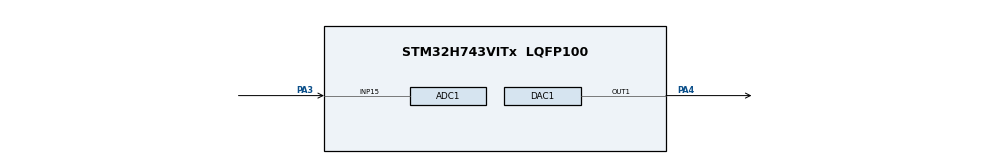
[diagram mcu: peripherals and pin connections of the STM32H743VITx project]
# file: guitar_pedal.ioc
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ADC1.Channel-0\#ChannelRegularConversion=ADC_CHANNEL_15
ADC1.ConversionDataManagement=ADC_CONVERSIONDATA_DMA_CIRCULAR
ADC1.ExternalTrigConv=ADC_EXTERNALTRIG_T6_TRGO
ADC1.NbrOfConversion=1
ADC1.NbrOfConversionFlag=1
ADC1.OffsetNumber-0\#ChannelRegularConversion=ADC_OFFSET_NONE
ADC1.OffsetSignedSaturation-0\#ChannelRegularConversion=DISABLE
ADC1.Rank-0\#ChannelRegularConversion=1
ADC1.SamplingTime-0\#ChannelRegularConversion=ADC_SAMPLETIME_1CYCLE_5
ADC1.master=1
DAC1.DAC_Channel-DAC_OUT1=DAC_CHANNEL_1
DAC1.DAC_Trigger-DAC_OUT1=DAC_TRIGGER_T6_TRGO
Dma.ADC1.0.Direction=DMA_PERIPH_TO_MEMORY
Dma.ADC1.0.EventEnable=DISABLE
Dma.ADC1.0.FIFOMode=DMA_FIFOMODE_DISABLE
Dma.ADC1.0.Instance=DMA1_Stream0
Dma.ADC1.0.MemDataAlignment=DMA_MDATAALIGN_HALFWORD
Dma.ADC1.0.MemInc=DMA_MINC_ENABLE
Dma.ADC1.0.Mode=DMA_CIRCULAR
Dma.ADC1.0.PeriphDataAlignment=DMA_PDATAALIGN_HALFWORD
Dma.ADC1.0.PeriphInc=DMA_PINC_DISABLE
Dma.ADC1.0.Polarity=HAL_DMAMUX_REQ_GEN_RISING
Dma.ADC1.0.Priority=DMA_PRIORITY_LOW
Dma.ADC1.0.RequestNumber=1
Dma.ADC1.0.SignalID=NONE
Dma.ADC1.0.SyncEnable=DISABLE
Dma.ADC1.0.SyncPolarity=HAL_DMAMUX_SYNC_NO_EVENT
Dma.ADC1.0.SyncRequestNumber=1
Dma.ADC1.0.SyncSignalID=NONE
Dma.DAC1_CH1.1.Direction=DMA_MEMORY_TO_PERIPH
Dma.DAC1_CH1.1.EventEnable=DISABLE
Dma.DAC1_CH1.1.FIFOMode=DMA_FIFOMODE_DISABLE
Dma.DAC1_CH1.1.Instance=DMA1_Stream1
Dma.DAC1_CH1.1.MemDataAlignment=DMA_MDATAALIGN_HALFWORD
Dma.DAC1_CH1.1.MemInc=DMA_MINC_ENABLE
Dma.DAC1_CH1.1.Mode=DMA_CIRCULAR
Dma.DAC1_CH1.1.PeriphDataAlignment=DMA_PDATAALIGN_HALFWORD
Dma.DAC1_CH1.1.PeriphInc=DMA_PINC_DISABLE
Dma.DAC1_CH1.1.Polarity=HAL_DMAMUX_REQ_GEN_RISING
Dma.DAC1_CH1.1.Priority=DMA_PRIORITY_LOW
Dma.DAC1_CH1.1.RequestNumber=1
Dma.DAC1_CH1.1.SignalID=NONE
Dma.DAC1_CH1.1.SyncEnable=DISABLE
Dma.DAC1_CH1.1.SyncPolarity=HAL_DMAMUX_SYNC_NO_EVENT
Dma.DAC1_CH1.1.SyncRequestNumber=1
Dma.DAC1_CH1.1.SyncSignalID=NONE
Dma.Request0=ADC1
Dma.Request1=DAC1_CH1
Mcu.Family=STM32H7
Mcu.Name=STM32H743VITx
Mcu.Package=LQFP100
NVIC.DMA1_Stream0_IRQn=true\:0\:0\:false\:false\:true\:false\:true\:true
NVIC.DMA1_Stream1_IRQn=true\:0\:0\:false\:false\:true\:false\:true\:true
NVIC.PriorityGroup=NVIC_PRIORITYGROUP_4
PA3.Signal=ADCx_INP15
PA4.Signal=COMP_DAC11_group
PH0-OSC_IN\ (PH0).Mode=HSE-External-Oscillator
PH0-OSC_IN\ (PH0).Signal=RCC_OSC_IN
PH1-OSC_OUT\ (PH1).Mode=HSE-External-Oscillator
PH1-OSC_OUT\ (PH1).Signal=RCC_OSC_OUT
ProjectManager.HeapSize=0x200
ProjectManager.StackSize=0x400
ProjectManager.TargetToolchain=CMake
RCC.ADCFreq_Value=75000000
RCC.APB1Freq_Value=120000000
RCC.APB2Freq_Value=120000000
RCC.APB3Freq_Value=120000000
RCC.APB4Freq_Value=120000000
RCC.CortexFreq_Value=480000000
RCC.D1PPRE=RCC_APB3_DIV2
RCC.D2PPRE1=RCC_APB1_DIV2
RCC.D2PPRE2=RCC_APB2_DIV2
RCC.D3PPRE=RCC_APB4_DIV2
RCC.DIVM1=8
RCC.DIVM2=4
RCC.DIVN1=120
RCC.DIVN2=9
RCC.HCLKFreq_Value=240000000
RCC.HPRE=RCC_HCLK_DIV2
RCC.PLL2FRACN=3072
RCC.PLLFRACN=0
RCC.SYSCLKFreq_VALUE=480000000
RCC.SYSCLKSource=RCC_SYSCLKSOURCE_PLLCLK
RCC.USBFreq_Value=480000000
SH.ADCx_INP15.0=ADC1_INP15,IN15-Single-Ended
SH.COMP_DAC11_group.0=DAC1_OUT1,DAC_OUT1
TIM6.Period=5000-1
TIM6.Prescaler=0
TIM6.TIM_MasterOutputTrigger=TIM_TRGO_UPDATE
VP_MEMORYMAP_VS_MEMORYMAP.Mode=CurAppReg
VP_TIM6_VS_ClockSourceINT.Mode=Enable_Timer
board=custom

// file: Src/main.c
/* USER CODE BEGIN Header */
/**
 ******************************************************************************
 * @file           : main.c
 * @brief          : Main program body
 ******************************************************************************
 * @attention
 *
 * Copyright (c) 2025 STMicroelectronics.
 * All rights reserved.
 *
 * This software is licensed under terms that can be found in the LICENSE file
 * in the root directory of this software component.
 * If no LICENSE file comes with this software, it is provided AS-IS.
 *
 ******************************************************************************
 */
/* USER CODE END Header */
#include "main.h"
#include "adc.h"
#include "dac.h"
#include "dma.h"
#include "tim.h"
#include "gpio.h"

/* USER CODE BEGIN Includes */
#include "dsp.h"

/* USER CODE END Includes */

/* USER CODE BEGIN PD */
#define N 256
#define halfN 128

/* USER CODE END PD */

/* USER CODE BEGIN PV */
// DMA1 cannot access DTCM RAM on STM32H7; place buffers in D2 SRAM.
__attribute__((section(".dma_buffer"))) uint16_t adcBuffer[N];
__attribute__((section(".dma_buffer"))) uint16_t dacBuffer[N];

volatile uint32_t dbg_halfCpltCount = 0;
volatile uint32_t dbg_cpltCount = 0;
volatile uint16_t dbg_adcSnapshot[4];
volatile uint16_t dbg_adcMin = 0xFFFF;
volatile uint16_t dbg_adcMax = 0;
volatile uint16_t dbg_dacSnapshot[4];

volatile uint32_t dbg_init_progress = 0;
volatile uint32_t dbg_reset_cause = 0;
volatile uint32_t dbg_fault_type = 0;
volatile uint32_t dbg_fault_CFSR = 0;
volatile uint32_t dbg_fault_HFSR = 0;
volatile uint32_t dbg_fault_MMFAR = 0;
volatile uint32_t dbg_fault_BFAR = 0;
volatile uint32_t dbg_error_handler_hit = 0;

/* USER CODE END PV */

void SystemClock_Config(void);
/* USER CODE BEGIN PFP */
void dsp_algorithm(uint16_t *input, uint16_t *output, int startindex,
                   int endindex);

/* USER CODE END PFP */

int main(void)
{

  /* USER CODE BEGIN 1 */
  // Force-reset peripherals: a debug-reset leaves them mid-operation.
  __HAL_RCC_DMA1_CLK_ENABLE();
  __HAL_RCC_DMA1_FORCE_RESET();
  __HAL_RCC_DMA1_RELEASE_RESET();

  NVIC_DisableIRQ(DMA1_Stream0_IRQn);
  NVIC_DisableIRQ(DMA1_Stream1_IRQn);
  NVIC_DisableIRQ(DMAMUX1_OVR_IRQn);
  NVIC_ClearPendingIRQ(DMA1_Stream0_IRQn);
  NVIC_ClearPendingIRQ(DMA1_Stream1_IRQn);
  NVIC_ClearPendingIRQ(DMAMUX1_OVR_IRQn);

  __HAL_RCC_ADC12_CLK_ENABLE();
  __HAL_RCC_ADC12_FORCE_RESET();
  __HAL_RCC_ADC12_RELEASE_RESET();

  __HAL_RCC_DAC12_CLK_ENABLE();
  __HAL_RCC_DAC12_FORCE_RESET();
  __HAL_RCC_DAC12_RELEASE_RESET();

  __HAL_RCC_TIM6_CLK_ENABLE();
  __HAL_RCC_TIM6_FORCE_RESET();
  __HAL_RCC_TIM6_RELEASE_RESET();

  dbg_reset_cause = RCC->RSR;
  __HAL_RCC_CLEAR_RESET_FLAGS();
  /* USER CODE END 1 */

  /* MCU Configuration--------------------------------------------------------*/

  /* Reset of all peripherals, Initializes the Flash interface and the Systick. */
  HAL_Init();

  /* USER CODE BEGIN Init */
  dbg_init_progress = 1;
  /* USER CODE END Init */

  /* Configure the system clock */
  SystemClock_Config();

  /* USER CODE BEGIN SysInit */
  dbg_init_progress = 2;
  /* USER CODE END SysInit */

  /* Initialize all configured peripherals */
  MX_GPIO_Init();
  dbg_init_progress = 3;
  MX_DMA_Init();
  dbg_init_progress = 4;
  MX_ADC1_Init();
  dbg_init_progress = 5;
  MX_DAC1_Init();
  dbg_init_progress = 6;
  MX_TIM6_Init();
  dbg_init_progress = 7;
  /* USER CODE BEGIN 2 */
  HAL_ADC_Start_DMA(&hadc1, (uint32_t *)adcBuffer, N);
  HAL_DAC_Start_DMA(&hdac1, DAC_CHANNEL_1, (uint32_t *)dacBuffer, N,
                    DAC_ALIGN_12B_R);
  HAL_TIM_Base_Start(&htim6);
  dbg_init_progress = 8;
  /* USER CODE END 2 */

  /* Infinite loop */
  /* USER CODE BEGIN WHILE */
  while (1) {
    dbg_init_progress = 9;
    /* USER CODE END WHILE */

  }
}

void SystemClock_Config(void)
{
  RCC_OscInitTypeDef RCC_OscInitStruct = {0};
  RCC_ClkInitTypeDef RCC_ClkInitStruct = {0};

  /** Supply configuration update enable
  */
  HAL_PWREx_ConfigSupply(PWR_LDO_SUPPLY);

  /** Configure the main internal regulator output voltage
  */
  __HAL_PWR_VOLTAGESCALING_CONFIG(PWR_REGULATOR_VOLTAGE_SCALE0);

  while(!__HAL_PWR_GET_FLAG(PWR_FLAG_VOSRDY)) {}

  /** Initializes the RCC Oscillators according to the specified parameters
  * in the RCC_OscInitTypeDef structure.
  * HSI 64MHz -> PLL -> 480MHz SYSCLK.
  */
  RCC_OscInitStruct.OscillatorType = RCC_OSCILLATORTYPE_HSI;
  RCC_OscInitStruct.HSIState = RCC_HSI_DIV1;
  RCC_OscInitStruct.HSICalibrationValue = RCC_HSICALIBRATION_DEFAULT;
  RCC_OscInitStruct.PLL.PLLState = RCC_PLL_ON;
  RCC_OscInitStruct.PLL.PLLSource = RCC_PLLSOURCE_HSI;
  RCC_OscInitStruct.PLL.PLLM = 8;
  RCC_OscInitStruct.PLL.PLLN = 120;
  RCC_OscInitStruct.PLL.PLLP = 2;
  RCC_OscInitStruct.PLL.PLLQ = 2;
  RCC_OscInitStruct.PLL.PLLR = 2;
  RCC_OscInitStruct.PLL.PLLRGE = RCC_PLL1VCIRANGE_3;
  RCC_OscInitStruct.PLL.PLLVCOSEL = RCC_PLL1VCOWIDE;
  RCC_OscInitStruct.PLL.PLLFRACN = 0;
  if (HAL_RCC_OscConfig(&RCC_OscInitStruct) != HAL_OK)
  {
    Error_Handler();
  }

  /** Initializes the CPU, AHB and APB buses clocks
  */
  RCC_ClkInitStruct.ClockType = RCC_CLOCKTYPE_HCLK|RCC_CLOCKTYPE_SYSCLK
                              |RCC_CLOCKTYPE_PCLK1|RCC_CLOCKTYPE_PCLK2
                              |RCC_CLOCKTYPE_D3PCLK1|RCC_CLOCKTYPE_D1PCLK1;
  RCC_ClkInitStruct.SYSCLKSource = RCC_SYSCLKSOURCE_PLLCLK;
  RCC_ClkInitStruct.SYSCLKDivider = RCC_SYSCLK_DIV1;
  RCC_ClkInitStruct.AHBCLKDivider = RCC_HCLK_DIV2;
  RCC_ClkInitStruct.APB3CLKDivider = RCC_APB3_DIV2;
  RCC_ClkInitStruct.APB1CLKDivider = RCC_APB1_DIV2;
  RCC_ClkInitStruct.APB2CLKDivider = RCC_APB2_DIV2;
  RCC_ClkInitStruct.APB4CLKDivider = RCC_APB4_DIV2;

  if (HAL_RCC_ClockConfig(&RCC_ClkInitStruct, FLASH_LATENCY_4) != HAL_OK)
  {
    Error_Handler();
  }
}

/* USER CODE BEGIN 4 */
void HAL_ADC_ConvCpltCallback(ADC_HandleTypeDef *hadc) {
  dsp_algorithm(adcBuffer, dacBuffer, halfN, N);
}

void HAL_ADC_ConvHalfCpltCallback(ADC_HandleTypeDef *hadc) {
  dbg_halfCpltCount++;
  dsp_algorithm(adcBuffer, dacBuffer, 0, halfN);
}
/* USER CODE END 4 */

void Error_Handler(void)
{
  /* USER CODE BEGIN Error_Handler_Debug */
  dbg_error_handler_hit = 1;
  __disable_irq();
  while (1) {
    __NOP();
  }
  /* USER CODE END Error_Handler_Debug */
}
#ifdef USE_FULL_ASSERT
/**
  * @brief  Reports the name of the source file and the source line number
  *         where the assert_param error has occurred.
  * @param  file: pointer to the source file name
  * @param  line: assert_param error line source number
  * @retval None
  */
void assert_failed(uint8_t *file, uint32_t line)
{
  /* USER CODE BEGIN 6 */
  /* User can add his own implementation to report the file name and line
     number, ex: printf("Wrong parameters value: file %s on line %d\r\n", file,
     line) */
  /* USER CODE END 6 */
}
#endif /* USE_FULL_ASSERT */
